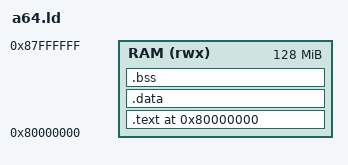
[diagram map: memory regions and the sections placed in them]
ENTRY(_start)

MEMORY {
  RAM (rwx) : ORIGIN = 0x80000000, LENGTH = 128M
}

SECTIONS {
  . = ORIGIN(RAM);
  .text : {
    *(.text.init)
    *(.text .text.*)
    *(.rodata .rodata.*)
  } > RAM

  .data : {
    *(.data .data.*)
  } > RAM

  .bss : {
    *(.bss .bss.*)
    *(COMMON)
  } > RAM

  . = ALIGN(8);
  _end = .;
}

